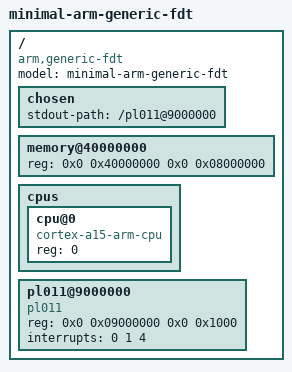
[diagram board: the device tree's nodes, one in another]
/dts-v1/;

/ {
    model = "minimal-arm-generic-fdt";
    compatible = "arm,generic-fdt";
    
    /* 
     * #address-cells: How many 32-bit integers it takes to represent a memory address.
     * #size-cells: How many 32-bit integers it takes to represent the length of a memory block.
     * We use 2 for both to support 64-bit addresses, even though our board is simple.
     */
    #address-cells = <2>;
    #size-cells = <2>;

    /* The chosen node is a standard place to pass parameters to the firmware/OS */
    chosen {
        stdout-path = "/pl011@9000000";
    };

    /* Define 128 MB of RAM starting at physical address 0x40000000 */
    memory@40000000 {
        reg = <0x0 0x40000000 0x0 0x08000000>;
    };

    cpus {
        #address-cells = <1>;
        #size-cells = <0>;
        
        cpu@0 {
            device_type = "cpu";
            /* 
             * INTERNALS NOTE: Standard Linux Device Trees use strings like "arm,cortex-a15".
             * However, qenode maps these strings DIRECTLY to internal QEMU Object Model (QOM) 
             * type names. The QOM name for this CPU is "cortex-a15-arm-cpu".
             */
            compatible = "cortex-a15-arm-cpu";
            reg = <0>;
        };
    };

    /* 
     * PL011 is a standard ARM UART (Serial Port). 
     * We map its registers to physical address 0x09000000.
     */
    pl011@9000000 {
        compatible = "pl011";
        reg = <0x0 0x09000000 0x0 0x1000>; /* Starts at 0x09000000, takes up 4KB (0x1000) */
        interrupts = <0 1 4>;
    };
};
